# f2838x_cm_dcsm_z1_regs register map
Vendor: Texas Instruments
Peripheral module from a debugger description file (folder C2000).
Address unit: 16 bits
Registers are 32-bit, read-only, no defined reset value unless marked. A register's access mark holds for its fields unless they carry their own. Offsets are as the file gives them; lines under a group give offsets from that group; [hi:lo] are bit positions; {n}, {i} and the like mark numbered series; 'fields as' and 'values as' point back to an identical list; <NAME> marks a mode.

## DCSM_Z1_REGS — DCSM Z1 Registers
0x00 Z1_LINKPOINTER — Zone 1 Link Pointer
  [13:0] LINKPOINTER — Zone1 LINK Pointer
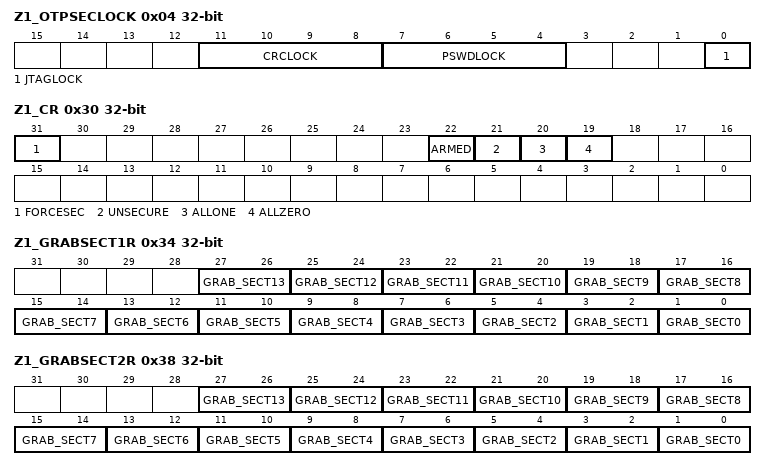
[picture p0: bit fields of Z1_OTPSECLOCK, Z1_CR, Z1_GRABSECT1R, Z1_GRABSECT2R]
0x04 Z1_OTPSECLOCK — Zone 1 OTP Secure Lock
  [11:8] CRCLOCK — Zone1 CRC Lock.
  [7:4] PSWDLOCK — Zone1 Password Lock.
  [0] JTAGLOCK — JTAG Lock Status
0x08 Z1_JLM_ENABLE — Zone 1 JTAGLOCK Enable Register
  [3:0] Z1_JLM_ENABLE — Zone1 JLM_ENABLE register.
0x0C Z1_LINKPOINTERERR — Link Pointer Error
  [13:0] Z1_LINKPOINTERERR — Error to Resolve Z1 Link pointer from OTP loaded values
{0xC+4i} Z1_GPREG{i} (i=1..4) — Zone 1 General Purpose Register-{i}
  [31:0] GPREG{i} — General Purpose Register-{i}
0x20 Z1_CSMKEY0 rw — Zone 1 CSM Key 0
  [31:0] Z1_CSMKEY0 — Word0 to unlock Zone1, should match Z1_CSMPSWD0.
{0x20+4i} Z1_CSMKEY{i} rw (i=1..3) — Zone 1 CSM Key {i}
  [31:0] Z1_CSMKEY{i} — Word{i} to unlock Zone1, should match Z1_CSMPSWD{i}
0x30 Z1_CR access per field — Zone 1 CSM Control Register
  [31] FORCESEC rw — Force Secure
  [22] ARMED ro — CSM Passwords Read Status
  [21] UNSECURE ro — CSMPSWD Match CSMKEY
  [20] ALLONE ro — CSMPSWD All Ones
  [19] ALLZERO ro — CSMPSWD All Zeros
0x34 Z1_GRABSECT1R — Zone 1 Grab Flash Status Register 1
  [2n+1:2n] GRAB_SECT{n} (n=0..13) — Grab Flash Sector {n} in CPU1 BANK
0x38 Z1_GRABSECT2R — Zone 1 Grab Flash Status Register 2
  [2n+1:2n] GRAB_SECT{n} (n=0..13) — Grab Flash Sector {n} in CM BANK
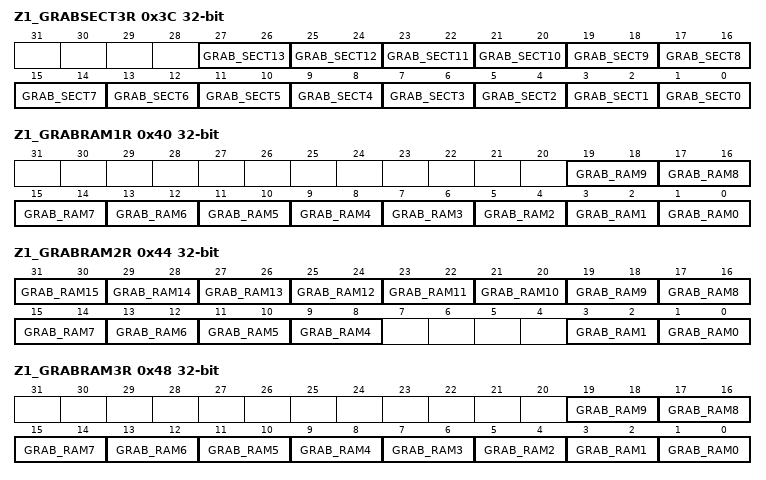
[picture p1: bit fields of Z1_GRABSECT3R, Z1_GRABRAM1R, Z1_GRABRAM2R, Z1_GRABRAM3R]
0x3C Z1_GRABSECT3R — Zone 1 Grab Flash Status Register 3
  [2n+1:2n] GRAB_SECT{n} (n=0..13) — Grab Flash Sector {n} in CPU2 BANK
0x40 Z1_GRABRAM1R — Zone 1 Grab RAM Status Register 1
  [19:18] GRAB_RAM9 — Grab RAM CPU1.D1
  [17:16] GRAB_RAM8 — Grab RAM CPU1.D0
  [2n+1:2n] GRAB_RAM{n} (n=0..7) — Grab RAM CPU1.LS{n}
0x44 Z1_GRABRAM2R — Zone 1 Grab RAM Status Register 2
  [31:30] GRAB_RAM15 — Grab RAM CPU2TOCPU1 MSGRAM0_H
  [29:28] GRAB_RAM14 — Grab RAM CPU2TOCPU1 MSGRAM0_L
  [27:26] GRAB_RAM13 — Grab RAM CPU1TOCPU2 MSGRAM0_H
  [25:24] GRAB_RAM12 — Grab RAM CPU1TOCPU2 MSGRAM0_L
  [23:22] GRAB_RAM11 — Grab RAM CMTOCPU2 MSGRAM0_H
  [21:20] GRAB_RAM10 — Grab RAM CMTOCPU2 MSGRAM0_L
  [19:18] GRAB_RAM9 — Grab RAM CPU2TOCM MSGRAM0_H
  [17:16] GRAB_RAM8 — Grab RAM CPU2TOCM MSGRAM0_L
  [15:14] GRAB_RAM7 — Grab RAM CMTOCPU1 MSGRAM0_H
  [13:12] GRAB_RAM6 — Grab RAM CMTOCPU1 MSGRAM0_L
  [11:10] GRAB_RAM5 — Grab RAM CPU1TOCM MSGRAM0_H
  [9:8] GRAB_RAM4 — Grab RAM CPU1TOCM MSGRAM0_L
  [3:2] GRAB_RAM1 — Grab RAM CM.C1
  [1:0] GRAB_RAM0 — Grab RAM CM.C0
0x48 Z1_GRABRAM3R — Zone 1 Grab RAM Status Register 3
  [19:18] GRAB_RAM9 — Grab RAM CPU2.D1
  [17:16] GRAB_RAM8 — Grab RAM CPU2.D0
  [2n+1:2n] GRAB_RAM{n} (n=0..7) — Grab RAM CPU2.LS{n}
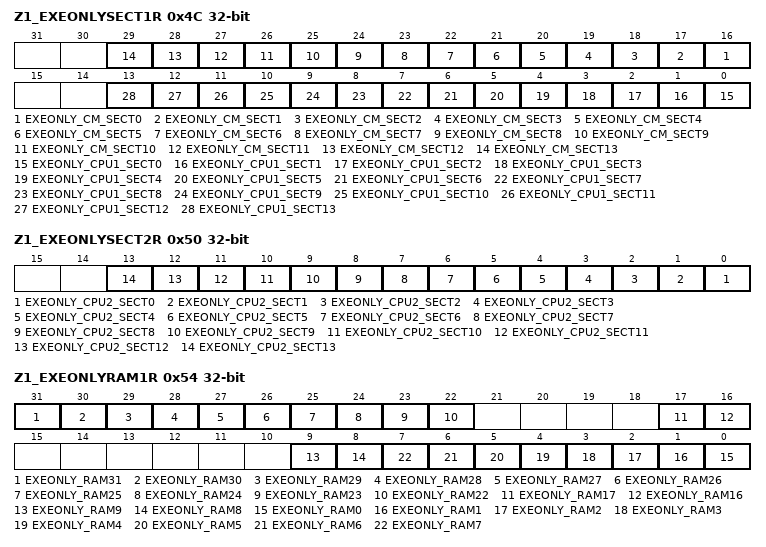
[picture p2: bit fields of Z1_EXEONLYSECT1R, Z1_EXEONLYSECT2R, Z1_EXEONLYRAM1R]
0x4C Z1_EXEONLYSECT1R — Zone 1 Execute Only Flash Status Register 1
  [n+16] EXEONLY_CM_SECT{n} (n=0..13) — Execute-Only Flash Sector {n} in flash CM BANK
  [n] EXEONLY_CPU1_SECT{n} (n=0..13) — Execute-Only Flash Sector {n} in flash CPU1 BANK
0x50 Z1_EXEONLYSECT2R — Zone 1 Execute Only Flash Status Register 2
  [n] EXEONLY_CPU2_SECT{n} (n=0..13) — Execute-Only Flash Sector {n} in flash CPU2 BANK
0x54 Z1_EXEONLYRAM1R — Zone 1 Execute Only RAM Status Register 1
  [31] EXEONLY_RAM31 — Execute-Only RAM CPU2.LS0
  [30] EXEONLY_RAM30 — Execute-Only RAM CPU2.LS1
  [29] EXEONLY_RAM29 — Execute-Only RAM CPU2.LS2
  [28] EXEONLY_RAM28 — Execute-Only RAM CPU2.LS3
  [27] EXEONLY_RAM27 — Execute-Only RAM CPU2.LS4
  [26] EXEONLY_RAM26 — Execute-Only RAM CPU2.LS5
  [25] EXEONLY_RAM25 — Execute-Only RAM CPU2.LS6
  [24] EXEONLY_RAM24 — Execute-Only RAM CPU2.LS7
  [23] EXEONLY_RAM23 — Execute-Only RAM CPU2.D0
  [22] EXEONLY_RAM22 — Execute-Only RAM CPU2.D1
  [17] EXEONLY_RAM17 — Execute-Only RAM on CM.C1
  [16] EXEONLY_RAM16 — Execute-Only RAM on CM.C0
  [9] EXEONLY_RAM9 — Execute-Only RAM CPU1.D1
  [8] EXEONLY_RAM8 — Execute-Only RAM CPU1.D0
  [n] EXEONLY_RAM{n} (n=0..7) — Execute-Only RAM CPU1.LS{n}
{0x5C+4i} Z1_JTAGKEY{i} (i=0..3) — JTAG Unlock Key Register {i}
  [31:0] KEY{i} — JTAGKEY Bits {32i+31}:{32i}
{0x6C+4i} Z1_CMACKEY{i} (i=0..3) — Secure Boot CMAC Key Status Register {i}
  [31:0] KEY{i} — CMACKEY Bits {32i+31}:{32i}
